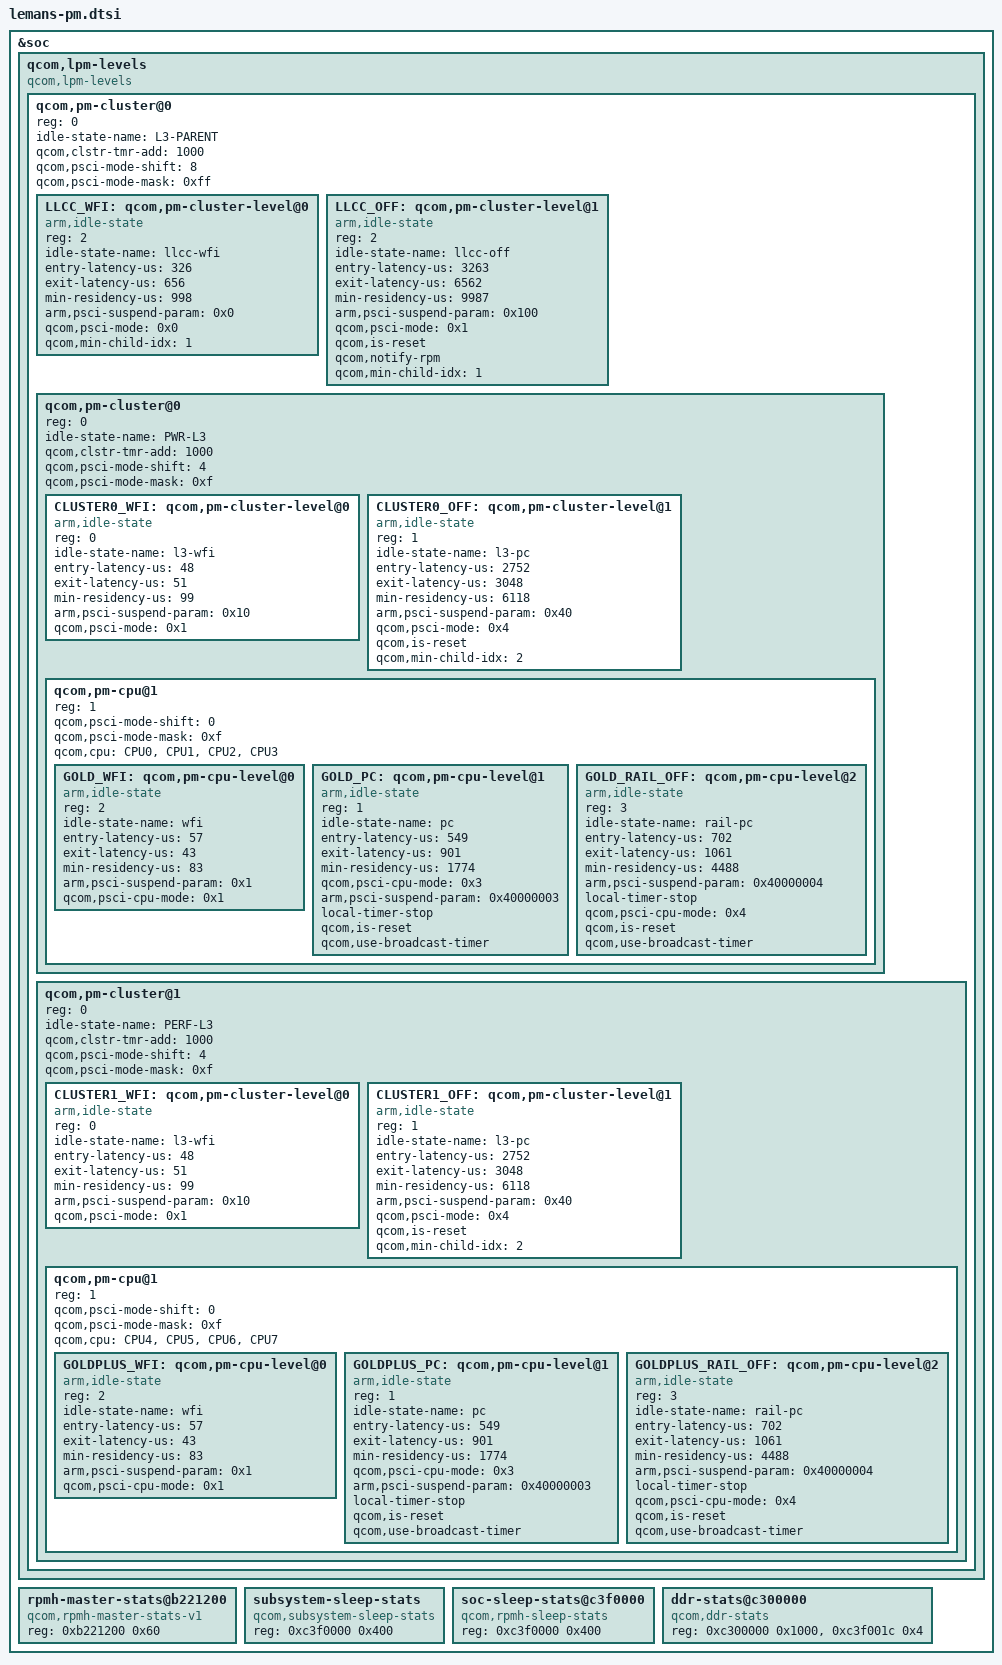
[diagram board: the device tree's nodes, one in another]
&soc {
	qcom,lpm-levels {
		compatible = "qcom,lpm-levels";
		#address-cells = <1>;
		#size-cells = <0>;

		qcom,pm-cluster@0 {
			reg = <0>;
			#address-cells = <1>;
			#size-cells = <0>;
			idle-state-name = "L3-PARENT";
			qcom,clstr-tmr-add = <1000>;
			qcom,psci-mode-shift = <8>;
			qcom,psci-mode-mask = <0xff>;

			LLCC_WFI: qcom,pm-cluster-level@0 { /* Dummy RSC */
				reg = <2>;
				compatible = "arm,idle-state";
				idle-state-name = "llcc-wfi";
				entry-latency-us = <326>;
				exit-latency-us = <656>;
				min-residency-us = <998>;
				arm,psci-suspend-param = <0x0>;
				qcom,psci-mode = <0x0>;
				qcom,min-child-idx = <1>;
			};

			LLCC_OFF: qcom,pm-cluster-level@1 { /* AOSS sleep */
				reg = <2>;
				compatible = "arm,idle-state";
				idle-state-name = "llcc-off";
				entry-latency-us = <3263>;
				exit-latency-us = <6562>;
				min-residency-us = <9987>;
				arm,psci-suspend-param = <0x100>;
				qcom,psci-mode = <0x1>;
				qcom,is-reset;
				qcom,notify-rpm;
				qcom,min-child-idx = <1>;
			};

			qcom,pm-cluster@0 {
				reg = <0>;
				#address-cells = <1>;
				#size-cells = <0>;
				idle-state-name = "PWR-L3";
				qcom,clstr-tmr-add = <1000>;
				qcom,psci-mode-shift = <4>;
				qcom,psci-mode-mask = <0xf>;

				CLUSTER0_WFI: qcom,pm-cluster-level@0 { /* D1 */
					reg = <0>;
					compatible = "arm,idle-state";
					idle-state-name = "l3-wfi";
					entry-latency-us = <48>;
					exit-latency-us = <51>;
					min-residency-us = <99>;
					arm,psci-suspend-param = <0x10>;
					qcom,psci-mode = <0x1>;
				};

				CLUSTER0_OFF: qcom,pm-cluster-level@1 { /* D4 */
					reg = <1>;
					compatible = "arm,idle-state";
					idle-state-name = "l3-pc";
					entry-latency-us = <2752>;
					exit-latency-us = <3048>;
					min-residency-us = <6118>;
					arm,psci-suspend-param = <0x40>;
					qcom,psci-mode = <0x4>;
					qcom,is-reset;
					qcom,min-child-idx = <2>;
				};

				qcom,pm-cpu@1 {
					reg = <1>;
					#address-cells = <1>;
					#size-cells = <0>;
					qcom,psci-mode-shift = <0>;
					qcom,psci-mode-mask = <0xf>;
					qcom,cpu = <&CPU0 &CPU1 &CPU2 &CPU3>;

					GOLD_WFI: qcom,pm-cpu-level@0 { /* C1 */
						reg = <2>;
						compatible = "arm,idle-state";
						idle-state-name = "wfi";
						entry-latency-us = <57>;
						exit-latency-us = <43>;
						min-residency-us = <83>;
						arm,psci-suspend-param = <0x1>;
						qcom,psci-cpu-mode = <0x1>;
					};

					GOLD_PC: qcom,pm-cpu-level@1 {  /* C3 */
						reg = <1>;
						compatible = "arm,idle-state";
						idle-state-name = "pc";
						entry-latency-us = <549>;
						exit-latency-us = <901>;
						min-residency-us = <1774>;
						qcom,psci-cpu-mode = <0x3>;
						arm,psci-suspend-param = <0x40000003>;
						local-timer-stop;
						qcom,is-reset;
						qcom,use-broadcast-timer;
					};

					GOLD_RAIL_OFF: qcom,pm-cpu-level@2 {  /* C4 */
						reg = <3>;
						compatible = "arm,idle-state";
						idle-state-name = "rail-pc";
						entry-latency-us = <702>;
						exit-latency-us = <1061>;
						min-residency-us = <4488>;
						arm,psci-suspend-param = <0x40000004>;
						local-timer-stop;
						qcom,psci-cpu-mode = <0x4>;
						qcom,is-reset;
						qcom,use-broadcast-timer;
					};
				};
			};

			qcom,pm-cluster@1 {
				reg = <0>;
				#address-cells = <1>;
				#size-cells = <0>;
				idle-state-name = "PERF-L3";
				qcom,clstr-tmr-add = <1000>;
				qcom,psci-mode-shift = <4>;
				qcom,psci-mode-mask = <0xf>;

				CLUSTER1_WFI: qcom,pm-cluster-level@0 { /* D1 */
					reg = <0>;
					compatible = "arm,idle-state";
					idle-state-name = "l3-wfi";
					entry-latency-us = <48>;
					exit-latency-us = <51>;
					min-residency-us = <99>;
					arm,psci-suspend-param = <0x10>;
					qcom,psci-mode = <0x1>;
				};

				CLUSTER1_OFF: qcom,pm-cluster-level@1 { /* D4 */
					reg = <1>;
					compatible = "arm,idle-state";
					idle-state-name = "l3-pc";
					entry-latency-us = <2752>;
					exit-latency-us = <3048>;
					min-residency-us = <6118>;
					arm,psci-suspend-param = <0x40>;
					qcom,psci-mode = <0x4>;
					qcom,is-reset;
					qcom,min-child-idx = <2>;
				};

				qcom,pm-cpu@1 {
					reg = <1>;
					#address-cells = <1>;
					#size-cells = <0>;
					qcom,psci-mode-shift = <0>;
					qcom,psci-mode-mask = <0xf>;
					qcom,cpu = <&CPU4 &CPU5 &CPU6 &CPU7>;

					GOLDPLUS_WFI: qcom,pm-cpu-level@0 { /* C1 */
						reg = <2>;
						compatible = "arm,idle-state";
						idle-state-name = "wfi";
						entry-latency-us = <57>;
						exit-latency-us = <43>;
						min-residency-us = <83>;
						arm,psci-suspend-param = <0x1>;
						qcom,psci-cpu-mode = <0x1>;
					};

					GOLDPLUS_PC: qcom,pm-cpu-level@1 {  /* C3 */
						reg = <1>;
						compatible = "arm,idle-state";
						idle-state-name = "pc";
						entry-latency-us = <549>;
						exit-latency-us = <901>;
						min-residency-us = <1774>;
						qcom,psci-cpu-mode = <0x3>;
						arm,psci-suspend-param = <0x40000003>;
						local-timer-stop;
						qcom,is-reset;
						qcom,use-broadcast-timer;
					};

					GOLDPLUS_RAIL_OFF: qcom,pm-cpu-level@2 {  /* C4 */
						reg = <3>;
						compatible = "arm,idle-state";
						idle-state-name = "rail-pc";
						entry-latency-us = <702>;
						exit-latency-us = <1061>;
						min-residency-us = <4488>;
						arm,psci-suspend-param = <0x40000004>;
						local-timer-stop;
						qcom,psci-cpu-mode = <0x4>;
						qcom,is-reset;
						qcom,use-broadcast-timer;
					};
				};
			};
		};
	};

	rpmh-master-stats@b221200 {
		compatible = "qcom,rpmh-master-stats-v1";
		reg = <0xb221200 0x60>;
	};

	subsystem-sleep-stats {
		compatible = "qcom,subsystem-sleep-stats";
		reg = <0xc3f0000 0x400>;
	};

	soc-sleep-stats@c3f0000 {
		compatible = "qcom,rpmh-sleep-stats";
		reg = <0xc3f0000 0x400>;
	};

	ddr-stats@c300000 {
		compatible = "qcom,ddr-stats";
		reg = <0xc300000 0x1000>, <0xc3f001c 0x4>;
		reg-names = "phys_addr_base", "offset_addr";
	};

};
